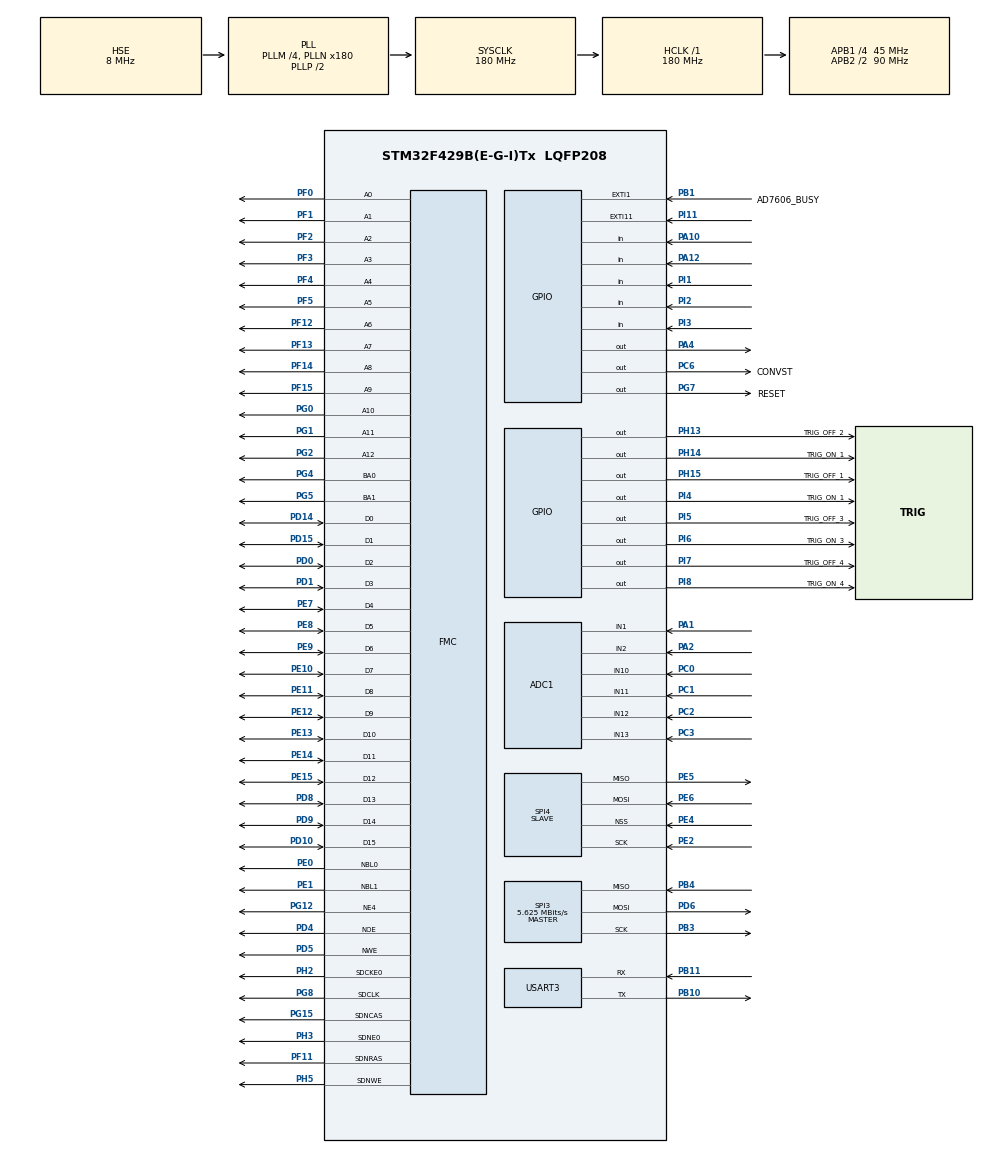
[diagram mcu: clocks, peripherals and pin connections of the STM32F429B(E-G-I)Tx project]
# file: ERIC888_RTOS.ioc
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ADC1.Channel-0\#ChannelRegularConversion=ADC_CHANNEL_1
ADC1.Channel-1\#ChannelRegularConversion=ADC_CHANNEL_2
ADC1.Channel-2\#ChannelRegularConversion=ADC_CHANNEL_10
ADC1.Channel-3\#ChannelRegularConversion=ADC_CHANNEL_11
ADC1.Channel-4\#ChannelRegularConversion=ADC_CHANNEL_12
ADC1.Channel-5\#ChannelRegularConversion=ADC_CHANNEL_13
ADC1.DMAContinuousRequests=ENABLE
ADC1.ExternalTrigConv=ADC_EXTERNALTRIGCONV_T3_TRGO
ADC1.NbrOfConversion=6
ADC1.NbrOfConversionFlag=1
ADC1.Rank-0\#ChannelRegularConversion=1
ADC1.Rank-1\#ChannelRegularConversion=2
ADC1.Rank-2\#ChannelRegularConversion=3
ADC1.Rank-3\#ChannelRegularConversion=4
ADC1.Rank-4\#ChannelRegularConversion=5
ADC1.Rank-5\#ChannelRegularConversion=6
ADC1.SamplingTime-0\#ChannelRegularConversion=ADC_SAMPLETIME_84CYCLES
ADC1.SamplingTime-1\#ChannelRegularConversion=ADC_SAMPLETIME_84CYCLES
ADC1.SamplingTime-2\#ChannelRegularConversion=ADC_SAMPLETIME_84CYCLES
ADC1.SamplingTime-3\#ChannelRegularConversion=ADC_SAMPLETIME_84CYCLES
ADC1.SamplingTime-4\#ChannelRegularConversion=ADC_SAMPLETIME_84CYCLES
ADC1.SamplingTime-5\#ChannelRegularConversion=ADC_SAMPLETIME_84CYCLES
ADC1.ScanConvMode=ENABLE
ADC1.master=1
Dma.ADC1.2.Direction=DMA_PERIPH_TO_MEMORY
Dma.ADC1.2.FIFOMode=DMA_FIFOMODE_DISABLE
Dma.ADC1.2.Instance=DMA2_Stream4
Dma.ADC1.2.MemDataAlignment=DMA_MDATAALIGN_HALFWORD
Dma.ADC1.2.MemInc=DMA_MINC_ENABLE
Dma.ADC1.2.Mode=DMA_CIRCULAR
Dma.ADC1.2.PeriphDataAlignment=DMA_PDATAALIGN_HALFWORD
Dma.ADC1.2.PeriphInc=DMA_PINC_DISABLE
Dma.ADC1.2.Priority=DMA_PRIORITY_LOW
Dma.Request0=SPI4_RX
Dma.Request1=SPI4_TX
Dma.Request2=ADC1
Dma.SPI4_RX.0.Direction=DMA_PERIPH_TO_MEMORY
Dma.SPI4_RX.0.FIFOMode=DMA_FIFOMODE_DISABLE
Dma.SPI4_RX.0.Instance=DMA2_Stream0
Dma.SPI4_RX.0.MemDataAlignment=DMA_MDATAALIGN_HALFWORD
Dma.SPI4_RX.0.MemInc=DMA_MINC_ENABLE
Dma.SPI4_RX.0.Mode=DMA_CIRCULAR
Dma.SPI4_RX.0.PeriphDataAlignment=DMA_PDATAALIGN_HALFWORD
Dma.SPI4_RX.0.PeriphInc=DMA_PINC_DISABLE
Dma.SPI4_RX.0.Priority=DMA_PRIORITY_VERY_HIGH
Dma.SPI4_TX.1.Direction=DMA_MEMORY_TO_PERIPH
Dma.SPI4_TX.1.FIFOMode=DMA_FIFOMODE_DISABLE
Dma.SPI4_TX.1.Instance=DMA2_Stream1
Dma.SPI4_TX.1.MemDataAlignment=DMA_MDATAALIGN_HALFWORD
Dma.SPI4_TX.1.MemInc=DMA_MINC_ENABLE
Dma.SPI4_TX.1.Mode=DMA_CIRCULAR
Dma.SPI4_TX.1.PeriphDataAlignment=DMA_PDATAALIGN_HALFWORD
Dma.SPI4_TX.1.PeriphInc=DMA_PINC_DISABLE
Dma.SPI4_TX.1.Priority=DMA_PRIORITY_VERY_HIGH
FMC.AddressSetupTime4=2
FMC.BusTurnAroundDuration4=2
FMC.CASLatency1=FMC_SDRAM_CAS_LATENCY_3
FMC.ColumnBitsNumber1=FMC_SDRAM_COLUMN_BITS_NUM_9
FMC.DataSetupTime4=6
FMC.ExitSelfRefreshDelay1=7
FMC.LoadToActiveDelay1=2
FMC.RCDDelay1=2
FMC.RPDelay1=2
FMC.RowCycleDelay1=7
FMC.SDClockPeriod1=FMC_SDRAM_CLOCK_PERIOD_2
FMC.SelfRefreshTime1=4
FMC.WriteOperation4=FMC_WRITE_OPERATION_ENABLE
FMC.WriteRecoveryTime1=3
FREERTOS.Tasks01=Task_01,0,512,StartTask01,Default,NULL,Dynamic,NULL,NULL;myTask_Calc,1,1024,StartTaskCalc,Default,NULL,Dynamic,NULL,NULL;myTask_Store,1,512,StartTaskStore,Default,NULL,Dynamic,NULL,NULL;myTask_Monitor,-2,256,StartTaskMonitor,Default,NULL,Dynamic,NULL,NULL
FREERTOS.configTOTAL_HEAP_SIZE=32768
IWDG.Prescaler=IWDG_PRESCALER_64
IWDG.Reload=1000
Mcu.Family=STM32F4
Mcu.Name=STM32F429B(E-G-I)Tx
Mcu.Package=LQFP208
NVIC.DMA2_Stream0_IRQn=true\:5\:0\:false\:false\:true\:true\:false\:true\:true
NVIC.DMA2_Stream1_IRQn=true\:5\:0\:false\:false\:true\:true\:false\:true\:true
NVIC.DMA2_Stream4_IRQn=true\:5\:0\:false\:false\:true\:true\:false\:true\:true
NVIC.EXTI1_IRQn=true\:5\:0\:false\:false\:true\:true\:true\:true\:true
NVIC.PriorityGroup=NVIC_PRIORITYGROUP_4
NVIC.TIM2_IRQn=true\:6\:0\:true\:false\:true\:true\:true\:true\:true
NVIC.TIM6_DAC_IRQn=true\:0\:0\:true\:false\:true\:false\:false\:true\:true
NVIC.TimeBase=TIM6_DAC_IRQn
NVIC.TimeBaseIP=TIM6
PA1.Signal=ADCx_IN1
PA10.Signal=GPIO_Input
PA12.Signal=GPIO_Input
PA13.Mode=Serial_Wire
PA13.Signal=SYS_JTMS-SWDIO
PA14.Mode=Serial_Wire
PA14.Signal=SYS_JTCK-SWCLK
PA2.Signal=ADCx_IN2
PA4.PinState=GPIO_PIN_SET
PA4.Signal=GPIO_Output
PB1.GPIO_Label=AD7606_BUSY
PB1.GPIO_ModeDefaultEXTI=GPIO_MODE_IT_FALLING
PB1.GPIO_PuPd=GPIO_PULLUP
PB1.Signal=GPXTI1
PB10.Mode=Asynchronous
PB10.Signal=USART3_TX
PB11.Mode=Asynchronous
PB11.Signal=USART3_RX
PB3.Mode=Full_Duplex_Master
PB3.Signal=SPI3_SCK
PB4.Mode=Full_Duplex_Master
PB4.Signal=SPI3_MISO
PB6.Signal=I2C1_SCL
PB9.Signal=I2C1_SDA
PC0.Signal=ADCx_IN10
PC1.Signal=ADCx_IN11
PC2.Signal=ADCx_IN12
PC3.Signal=ADCx_IN13
PC6.GPIO_Label=CONVST
PC6.Signal=GPIO_Output
PD0.Signal=FMC_D2_DA2
PD1.Signal=FMC_D3_DA3
PD10.Signal=FMC_D15_DA15
PD14.Signal=FMC_D0_DA0
PD15.Signal=FMC_D1_DA1
PD4.Signal=FMC_NOE
PD5.Signal=FMC_NWE
PD6.Mode=Full_Duplex_Master
PD6.Signal=SPI3_MOSI
PD8.Signal=FMC_D13_DA13
PD9.Signal=FMC_D14_DA14
PE0.Signal=FMC_NBL0
PE1.Signal=FMC_NBL1
PE10.Signal=FMC_D7_DA7
PE11.Signal=FMC_D8_DA8
PE12.Signal=FMC_D9_DA9
PE13.Signal=FMC_D10_DA10
PE14.Signal=FMC_D11_DA11
PE15.Signal=FMC_D12_DA12
PE2.Mode=Full_Duplex_Slave
PE2.Signal=SPI4_SCK
PE4.Mode=NSS_Signal_Hard_Input
PE4.Signal=SPI4_NSS
PE5.Mode=Full_Duplex_Slave
PE5.Signal=SPI4_MISO
PE6.Mode=Full_Duplex_Slave
PE6.Signal=SPI4_MOSI
PE7.Signal=FMC_D4_DA4
PE8.Signal=FMC_D5_DA5
PE9.Signal=FMC_D6_DA6
PF0.Signal=FMC_A0
PF1.Signal=FMC_A1
PF11.Signal=FMC_SDNRAS
PF12.Signal=FMC_A6
PF13.Signal=FMC_A7
PF14.Signal=FMC_A8
PF15.Signal=FMC_A9
PF2.Signal=FMC_A2
PF3.Signal=FMC_A3
PF4.Signal=FMC_A4
PF5.Signal=FMC_A5
PG0.Signal=FMC_A10
PG1.Signal=FMC_A11
PG12.Mode=NorPsramChipSelect4_4
PG12.Signal=FMC_NE4
PG15.Signal=FMC_SDNCAS
PG2.Signal=FMC_A12
PG4.Signal=FMC_A14_BA0
PG5.Signal=FMC_A15_BA1
PG7.GPIO_Label=RESET
PG7.Signal=GPIO_Output
PG8.Signal=FMC_SDCLK
PH0/OSC_IN.Mode=HSE-External-Oscillator
PH0/OSC_IN.Signal=RCC_OSC_IN
PH1/OSC_OUT.Mode=HSE-External-Oscillator
PH1/OSC_OUT.Signal=RCC_OSC_OUT
PH13.GPIO_Label=TRIG_OFF_2
PH13.GPIO_ModeDefaultOutputPP=GPIO_MODE_OUTPUT_PP
PH13.GPIO_PuPd=GPIO_NOPULL
PH13.GPIO_Speed=GPIO_SPEED_FREQ_VERY_HIGH
PH13.Signal=GPIO_Output
PH14.GPIO_Label=TRIG_ON_1
PH14.GPIO_ModeDefaultOutputPP=GPIO_MODE_OUTPUT_PP
PH14.GPIO_PuPd=GPIO_NOPULL
PH14.GPIO_Speed=GPIO_SPEED_FREQ_VERY_HIGH
PH14.Signal=GPIO_Output
PH15.GPIO_Label=TRIG_OFF_1
PH15.GPIO_ModeDefaultOutputPP=GPIO_MODE_OUTPUT_PP
PH15.GPIO_PuPd=GPIO_NOPULL
PH15.GPIO_Speed=GPIO_SPEED_FREQ_VERY_HIGH
PH15.Signal=GPIO_Output
PH2.Mode=SdramChipSelect1_1
PH2.Signal=FMC_SDCKE0
PH3.Mode=SdramChipSelect1_1
PH3.Signal=FMC_SDNE0
PH5.Signal=FMC_SDNWE
PI1.Signal=GPIO_Input
PI11.Signal=GPXTI11
PI2.Signal=GPIO_Input
PI3.Signal=GPIO_Input
PI4.GPIO_Label=TRIG_ON_1
PI4.GPIO_ModeDefaultOutputPP=GPIO_MODE_OUTPUT_PP
PI4.GPIO_PuPd=GPIO_NOPULL
PI4.GPIO_Speed=GPIO_SPEED_FREQ_VERY_HIGH
PI4.PinState=GPIO_PIN_RESET
PI4.Signal=GPIO_Output
PI5.GPIO_Label=TRIG_OFF_3
PI5.GPIO_ModeDefaultOutputPP=GPIO_MODE_OUTPUT_PP
PI5.GPIO_PuPd=GPIO_NOPULL
PI5.GPIO_Speed=GPIO_SPEED_FREQ_VERY_HIGH
PI5.Signal=GPIO_Output
PI6.GPIO_Label=TRIG_ON_3
PI6.GPIO_ModeDefaultOutputPP=GPIO_MODE_OUTPUT_PP
PI6.GPIO_PuPd=GPIO_NOPULL
PI6.GPIO_Speed=GPIO_SPEED_FREQ_VERY_HIGH
PI6.Signal=GPIO_Output
PI7.GPIO_Label=TRIG_OFF_4
PI7.GPIO_ModeDefaultOutputPP=GPIO_MODE_OUTPUT_PP
PI7.GPIO_PuPd=GPIO_NOPULL
PI7.GPIO_Speed=GPIO_SPEED_FREQ_VERY_HIGH
PI7.Signal=GPIO_Output
PI8.GPIO_Label=TRIG_ON_4
PI8.GPIO_ModeDefaultOutputPP=GPIO_MODE_OUTPUT_PP
PI8.GPIO_PuPd=GPIO_NOPULL
PI8.GPIO_Speed=GPIO_SPEED_FREQ_LOW
PI8.PinState=GPIO_PIN_RESET
PI8.Signal=GPIO_Output
ProjectManager.HeapSize=0x200
ProjectManager.StackSize=0x400
ProjectManager.TargetToolchain=Makefile
RCC.48MHZClocksFreq_Value=90000000
RCC.AHBFreq_Value=180000000
RCC.APB1CLKDivider=RCC_HCLK_DIV4
RCC.APB1Freq_Value=45000000
RCC.APB1TimFreq_Value=90000000
RCC.APB2CLKDivider=RCC_HCLK_DIV2
RCC.APB2Freq_Value=90000000
RCC.APB2TimFreq_Value=180000000
RCC.CortexFreq_Value=180000000
RCC.HCLKFreq_Value=180000000
RCC.HSE_VALUE=8000000
RCC.HSI_VALUE=16000000
RCC.LSE_VALUE=32768
RCC.PLLM=4
RCC.PLLN=180
RCC.PLLSourceVirtual=RCC_PLLSOURCE_HSE
RCC.SYSCLKFreq_VALUE=180000000
RCC.SYSCLKSource=RCC_SYSCLKSOURCE_PLLCLK
RCC.VCOOutputFreq_Value=360000000
SH.ADCx_IN1.0=ADC1_IN1,IN1
SH.ADCx_IN10.0=ADC1_IN10,IN10
SH.ADCx_IN11.0=ADC1_IN11,IN11
SH.ADCx_IN12.0=ADC1_IN12,IN12
SH.ADCx_IN13.0=ADC1_IN13,IN13
SH.ADCx_IN2.0=ADC1_IN2,IN2
SH.FMC_A0.0=FMC_A0,13b-sda1
SH.FMC_A0.1=FMC_A0,1b-a4
SH.FMC_A1.0=FMC_A1,13b-sda1
SH.FMC_A10.0=FMC_A10,13b-sda1
SH.FMC_A11.0=FMC_A11,13b-sda1
SH.FMC_A12.0=FMC_A12,13b-sda1
SH.FMC_A14_BA0.0=FMC_BA0,FourSdramBanks1
SH.FMC_A15_BA1.0=FMC_BA1,FourSdramBanks1
SH.FMC_A2.0=FMC_A2,13b-sda1
SH.FMC_A3.0=FMC_A3,13b-sda1
SH.FMC_A4.0=FMC_A4,13b-sda1
SH.FMC_A5.0=FMC_A5,13b-sda1
SH.FMC_A6.0=FMC_A6,13b-sda1
SH.FMC_A7.0=FMC_A7,13b-sda1
SH.FMC_A8.0=FMC_A8,13b-sda1
SH.FMC_A9.0=FMC_A9,13b-sda1
SH.FMC_D0_DA0.0=FMC_D0,sd-16b-d1
SH.FMC_D0_DA0.1=FMC_D0,16b-d4
SH.FMC_D10_DA10.0=FMC_D10,sd-16b-d1
SH.FMC_D10_DA10.1=FMC_D10,16b-d4
SH.FMC_D11_DA11.0=FMC_D11,sd-16b-d1
SH.FMC_D11_DA11.1=FMC_D11,16b-d4
SH.FMC_D12_DA12.0=FMC_D12,sd-16b-d1
SH.FMC_D12_DA12.1=FMC_D12,16b-d4
SH.FMC_D13_DA13.0=FMC_D13,sd-16b-d1
SH.FMC_D13_DA13.1=FMC_D13,16b-d4
SH.FMC_D14_DA14.0=FMC_D14,sd-16b-d1
SH.FMC_D14_DA14.1=FMC_D14,16b-d4
SH.FMC_D15_DA15.0=FMC_D15,sd-16b-d1
SH.FMC_D15_DA15.1=FMC_D15,16b-d4
SH.FMC_D1_DA1.0=FMC_D1,sd-16b-d1
SH.FMC_D1_DA1.1=FMC_D1,16b-d4
SH.FMC_D2_DA2.0=FMC_D2,sd-16b-d1
SH.FMC_D2_DA2.1=FMC_D2,16b-d4
SH.FMC_D3_DA3.0=FMC_D3,sd-16b-d1
SH.FMC_D3_DA3.1=FMC_D3,16b-d4
SH.FMC_D4_DA4.0=FMC_D4,sd-16b-d1
SH.FMC_D4_DA4.1=FMC_D4,16b-d4
SH.FMC_D5_DA5.0=FMC_D5,sd-16b-d1
SH.FMC_D5_DA5.1=FMC_D5,16b-d4
SH.FMC_D6_DA6.0=FMC_D6,sd-16b-d1
SH.FMC_D6_DA6.1=FMC_D6,16b-d4
SH.FMC_D7_DA7.0=FMC_D7,sd-16b-d1
SH.FMC_D7_DA7.1=FMC_D7,16b-d4
SH.FMC_D8_DA8.0=FMC_D8,sd-16b-d1
SH.FMC_D8_DA8.1=FMC_D8,16b-d4
SH.FMC_D9_DA9.0=FMC_D9,sd-16b-d1
SH.FMC_D9_DA9.1=FMC_D9,16b-d4
SH.FMC_NBL0.0=FMC_NBL0,Sd2ByteEnable1
SH.FMC_NBL1.0=FMC_NBL1,Sd2ByteEnable1
SH.FMC_NOE.0=FMC_NOE,Sram4
SH.FMC_NWE.0=FMC_NWE,Sram4
SH.FMC_SDCLK.0=FMC_SDCLK,13b-sda1
SH.FMC_SDNCAS.0=FMC_SDNCAS,13b-sda1
SH.FMC_SDNRAS.0=FMC_SDNRAS,13b-sda1
SH.FMC_SDNWE.0=FMC_SDNWE,13b-sda1
SPI3.BaudRatePrescaler=SPI_BAUDRATEPRESCALER_8
SPI3.CalculateBaudRate=5.625 MBits/s
SPI3.Direction=SPI_DIRECTION_2LINES
SPI3.Mode=SPI_MODE_MASTER
SPI3.VirtualType=VM_MASTER
SPI4.DataSize=SPI_DATASIZE_16BIT
SPI4.Direction=SPI_DIRECTION_2LINES
SPI4.Mode=SPI_MODE_SLAVE
SPI4.VirtualNSS=VM_NSSHARD
SPI4.VirtualType=VM_SLAVE
TIM2.AutoReloadPreload=TIM_AUTORELOAD_PRELOAD_ENABLE
TIM2.Period=99
TIM2.Prescaler=89
TIM3.Period=3515
TIM3.Prescaler=0
TIM3.TIM_MasterOutputTrigger=TIM_TRGO_UPDATE
USART3.VirtualMode=VM_ASYNC
VP_FREERTOS_VS_CMSIS_V1.Mode=CMSIS_V1
VP_IWDG_VS_IWDG.Mode=IWDG_Activate
VP_SYS_VS_tim6.Mode=TIM6
VP_TIM2_VS_ClockSourceINT.Mode=Internal
VP_TIM3_VS_ClockSourceINT.Mode=Internal
board=custom

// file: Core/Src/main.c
/* USER CODE BEGIN Header */
/**
 ******************************************************************************
 * @file           : main.c
 * @brief          : Main program body
 ******************************************************************************
 * @attention
 *
 * Copyright (c) 2026 STMicroelectronics.
 * All rights reserved.
 *
 * This software is licensed under terms that can be found in the LICENSE file
 * in the root directory of this software component.
 * If no LICENSE file comes with this software, it is provided AS-IS.
 *
 ******************************************************************************
 */
/* USER CODE END Header */
#include "main.h"
#include "cmsis_os.h"
#include "adc.h"
#include "dma.h"
#include "iwdg.h"
#include "spi.h"
#include "tim.h"
#include "usart.h"
#include "gpio.h"
#include "fmc.h"

/* USER CODE BEGIN Includes */
#include "bsp_sdram.h"
#include "bsp_ad7606.h"
#include "bsp_adc.h"
#include "bsp_kswitch.h"
#include "bsp_rs485.h"
#include "bsp_spiflash.h"
/* USER CODE END Includes */

/* USER CODE BEGIN PD */
// ERIC888 快切点火核心：AD7606 挂载在 FMC NE4，基地址 0x6C000000
#define AD7606_BASE_ADDR ((uint32_t)0x6C000000)
/* USER CODE END PD */

/* USER CODE BEGIN PV */
// 定义一个全局数组，用来存储 8 个通道的电压/电流实时数据
int16_t ad7606_data[8];
uint16_t adc_dma_buf[6];  // ADC1 DMA circular buffer (6 channels)
/* USER CODE END PV */

void SystemClock_Config(void);
void MX_FREERTOS_Init(void);

int main(void)
{

  /* MCU Configuration--------------------------------------------------------*/

  /* Reset of all peripherals, Initializes the Flash interface and the Systick. */
  HAL_Init();

  /* Configure the system clock */
  SystemClock_Config();

  /* Initialize all configured peripherals */
  MX_GPIO_Init();
  MX_DMA_Init();
  MX_FMC_Init();
  MX_SPI4_Init();
  MX_USART3_UART_Init();
  MX_ADC1_Init();
  MX_IWDG_Init();
  MX_TIM3_Init();
  MX_SPI3_Init();
  MX_TIM2_Init();
  /* USER CODE BEGIN 2 */
  // --- IO 补偿单元：180MHz 下 Very High 速率引脚必须开启 ---
  __HAL_RCC_SYSCFG_CLK_ENABLE();
  SYSCFG->CMPCR |= SYSCFG_CMPCR_CMP_PD;
  while (!(SYSCFG->CMPCR & SYSCFG_CMPCR_READY)) {}

  // --- PI8 (TRIG_ON_4) 速率强推 Very High (CubeMX 限制为 Low) ---
  GPIOI->OSPEEDR |= (3U << (8 * 2));  // bit[17:16] = 0b11

  // --- SDRAM 初始化序列 (W9825G6KH) ---
  if (BSP_SDRAM_Init(&hsdram1) != 0) {
    Error_Handler();  // SDRAM 初始化失败
  }

  // --- SDRAM 读写测试 (4KB) ---
  volatile int sdram_test_result = BSP_SDRAM_Test();
  // sdram_test_result: 0=通过, -1=失败，可通过调试器查看

  // --- AD7606 hardware reset ---
  BSP_AD7606_Reset();

  // --- SPI Flash init (SPI3 manual) ---
  BSP_SpiFlash_Init();
  volatile uint32_t flash_id = BSP_SpiFlash_ReadID();
  // flash_id: e.g. 0xEF4018 (W25Q128), check via debugger

  // --- ADC1 DMA start (TIM3 25.6kHz trigger, 6 channels) ---
  BSP_ADC_Start(&hadc1, &htim3, adc_dma_buf);

  // --- TIM3 CH1: hardware PWM CONVST at 25.6kHz (zero-ISR, zero-jitter) ---
  // TIM3 TRGO=Update triggers ADC; CH1 PWM outputs CONVST pulse on PC6
  HAL_TIM_PWM_Start(&htim3, TIM_CHANNEL_1);

  // --- EXTI1 (PB1 BUSY): priority=4, preempts SPI/UART(5+) ---
  // configLIBRARY_MAX_SYSCALL_INTERRUPT_PRIORITY=4, so FromISR APIs are safe
  HAL_NVIC_SetPriority(EXTI1_IRQn, 4, 0);
  /* USER CODE END 2 */

  /* Call init function for freertos objects (in cmsis_os2.c) */
  MX_FREERTOS_Init();

  /* Start scheduler */
  osKernelStart();

  /* We should never get here as control is now taken by the scheduler */

  /* Infinite loop */
  while (1) {

    /* USER CODE BEGIN 3 */
    // FreeRTOS scheduler took over, this loop is never reached
  }
  /* USER CODE END 3 */
}

void SystemClock_Config(void)
{
  RCC_OscInitTypeDef RCC_OscInitStruct = {0};
  RCC_ClkInitTypeDef RCC_ClkInitStruct = {0};

  /** Configure the main internal regulator output voltage
  */
  __HAL_RCC_PWR_CLK_ENABLE();
  __HAL_PWR_VOLTAGESCALING_CONFIG(PWR_REGULATOR_VOLTAGE_SCALE1);

  /** Initializes the RCC Oscillators according to the specified parameters
  * in the RCC_OscInitTypeDef structure.
  */
  RCC_OscInitStruct.OscillatorType = RCC_OSCILLATORTYPE_LSI|RCC_OSCILLATORTYPE_HSE;
  RCC_OscInitStruct.HSEState = RCC_HSE_ON;
  RCC_OscInitStruct.LSIState = RCC_LSI_ON;
  RCC_OscInitStruct.PLL.PLLState = RCC_PLL_ON;
  RCC_OscInitStruct.PLL.PLLSource = RCC_PLLSOURCE_HSE;
  RCC_OscInitStruct.PLL.PLLM = 4;
  RCC_OscInitStruct.PLL.PLLN = 180;
  RCC_OscInitStruct.PLL.PLLP = RCC_PLLP_DIV2;
  RCC_OscInitStruct.PLL.PLLQ = 4;
  if (HAL_RCC_OscConfig(&RCC_OscInitStruct) != HAL_OK)
  {
    Error_Handler();
  }

  /** Activate the Over-Drive mode
  */
  if (HAL_PWREx_EnableOverDrive() != HAL_OK)
  {
    Error_Handler();
  }

  /** Initializes the CPU, AHB and APB buses clocks
  */
  RCC_ClkInitStruct.ClockType = RCC_CLOCKTYPE_HCLK|RCC_CLOCKTYPE_SYSCLK
                              |RCC_CLOCKTYPE_PCLK1|RCC_CLOCKTYPE_PCLK2;
  RCC_ClkInitStruct.SYSCLKSource = RCC_SYSCLKSOURCE_PLLCLK;
  RCC_ClkInitStruct.AHBCLKDivider = RCC_SYSCLK_DIV1;
  RCC_ClkInitStruct.APB1CLKDivider = RCC_HCLK_DIV4;
  RCC_ClkInitStruct.APB2CLKDivider = RCC_HCLK_DIV2;

  if (HAL_RCC_ClockConfig(&RCC_ClkInitStruct, FLASH_LATENCY_5) != HAL_OK)
  {
    Error_Handler();
  }
}

void HAL_TIM_PeriodElapsedCallback(TIM_HandleTypeDef *htim)
{
  if (htim->Instance == TIM6)
  {
    HAL_IncTick();
  }
}

void Error_Handler(void)
{
  __disable_irq();
  while (1) {
  }
}
#ifdef USE_FULL_ASSERT
/**
  * @brief  Reports the name of the source file and the source line number
  *         where the assert_param error has occurred.
  * @param  file: pointer to the source file name
  * @param  line: assert_param error line source number
  * @retval None
  */
void assert_failed(uint8_t *file, uint32_t line)
{
  /* USER CODE BEGIN 6 */
  /* User can add his own implementation to report the file name and line
     number, ex: printf("Wrong parameters value: file %s on line %d\r\n", file,
     line) */
  /* USER CODE END 6 */
}
#endif /* USE_FULL_ASSERT */

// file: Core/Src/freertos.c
/* USER CODE BEGIN Header */
/**
  ******************************************************************************
  * File Name          : freertos.c
  * Description        : Code for freertos applications
  ******************************************************************************
  * @attention
  *
  * Copyright (c) 2026 STMicroelectronics.
  * All rights reserved.
  *
  * This software is licensed under terms that can be found in the LICENSE file
  * in the root directory of this software component.
  * If no LICENSE file comes with this software, it is provided AS-IS.
  *
  ******************************************************************************
  */
/* USER CODE END Header */

#include "FreeRTOS.h"
#include "task.h"
#include "main.h"
#include "cmsis_os.h"

/* USER CODE BEGIN Includes */
#include "bsp_ad7606.h"
#include "bsp_adc.h"
#include "bsp_kswitch.h"
#include "bsp_rs485.h"
#include "bsp_sdram.h"
#include "adc.h"
#include "tim.h"
#include "usart.h"
#include "iwdg.h"
#include "eric888_spi_protocol.h"
#include "bsp_spi_slave.h"
#include "spi.h"
#include "dsp_calc.h"
#include "fault_recorder.h"
#include "modbus_rtu.h"
/* USER CODE END Includes */

/* USER CODE BEGIN Variables */
extern uint16_t adc_dma_buf[6];
extern volatile uint32_t g_isr_count;
extern volatile uint32_t g_isr_cycles_max;

/* Task notification handle - used by EXTI1 ISR to wake Calc task */
volatile TaskHandle_t xCalcTaskHandle = NULL;

/* Ping-pong double buffer: ISR writes, Task reads, zero-race */
Eric888_DoubleBuffer g_adc_db;

/* Batch ring buffer: 2 x 512 samples in SDRAM for SPI bulk transfer */
Eric888_BatchRing g_batch_ring __attribute__((section(".sdram")));
/* NOTE: if .sdram section is not defined in linker, place in BSS: */
/* Eric888_BatchRing g_batch_ring; */
/* USER CODE END Variables */
osThreadId Task_01Handle;
osThreadId myTask_CalcHandle;
osThreadId myTask_StoreHandle;
osThreadId myTask_MonitorHandle;

void StartTask01(void const * argument);
void StartTaskCalc(void const * argument);
void StartTaskStore(void const * argument);
void StartTaskMonitor(void const * argument);

void MX_FREERTOS_Init(void); /* (MISRA C 2004 rule 8.1) */

/* GetIdleTaskMemory prototype (linked to static allocation support) */
void vApplicationGetIdleTaskMemory( StaticTask_t **ppxIdleTaskTCBBuffer, StackType_t **ppxIdleTaskStackBuffer, uint32_t *pulIdleTaskStackSize );

/* USER CODE BEGIN GET_IDLE_TASK_MEMORY */
static StaticTask_t xIdleTaskTCBBuffer;
static StackType_t xIdleStack[configMINIMAL_STACK_SIZE];

void vApplicationGetIdleTaskMemory( StaticTask_t **ppxIdleTaskTCBBuffer, StackType_t **ppxIdleTaskStackBuffer, uint32_t *pulIdleTaskStackSize )
{
  *ppxIdleTaskTCBBuffer = &xIdleTaskTCBBuffer;
  *ppxIdleTaskStackBuffer = &xIdleStack[0];
  *pulIdleTaskStackSize = configMINIMAL_STACK_SIZE;
  /* place for user code */
}
/* USER CODE END GET_IDLE_TASK_MEMORY */

/* GetTimerTaskMemory prototype (required when configUSE_TIMERS=1 + static alloc) */
void vApplicationGetTimerTaskMemory( StaticTask_t **ppxTimerTaskTCBBuffer, StackType_t **ppxTimerTaskStackBuffer, uint32_t *pulTimerTaskStackSize );

static StaticTask_t xTimerTaskTCBBuffer;
static StackType_t xTimerStack[configTIMER_TASK_STACK_DEPTH];

void vApplicationGetTimerTaskMemory( StaticTask_t **ppxTimerTaskTCBBuffer, StackType_t **ppxTimerTaskStackBuffer, uint32_t *pulTimerTaskStackSize )
{
  *ppxTimerTaskTCBBuffer = &xTimerTaskTCBBuffer;
  *ppxTimerTaskStackBuffer = &xTimerStack[0];
  *pulTimerTaskStackSize = configTIMER_TASK_STACK_DEPTH;
}

void MX_FREERTOS_Init(void) {

  /* Create the thread(s) */
  /* definition and creation of Task_01 */
  osThreadDef(Task_01, StartTask01, osPriorityNormal, 0, 512);
  Task_01Handle = osThreadCreate(osThread(Task_01), NULL);

  /* definition and creation of myTask_Calc */
  osThreadDef(myTask_Calc, StartTaskCalc, osPriorityAboveNormal, 0, 1024);
  myTask_CalcHandle = osThreadCreate(osThread(myTask_Calc), NULL);

  /* definition and creation of myTask_Store */
  osThreadDef(myTask_Store, StartTaskStore, osPriorityAboveNormal, 0, 512);
  myTask_StoreHandle = osThreadCreate(osThread(myTask_Store), NULL);

  /* definition and creation of myTask_Monitor */
  osThreadDef(myTask_Monitor, StartTaskMonitor, osPriorityLow, 0, 256);
  myTask_MonitorHandle = osThreadCreate(osThread(myTask_Monitor), NULL);

}

void StartTask01(void const * argument)
{
  /* USER CODE BEGIN StartTask01 */
  /* Communication task: SPI4 inter-board + RS485 Modbus */
  BSP_RS485_Init();
  BSP_SpiSlave_Init(&hspi4);
  Modbus_Init(&huart3);

  for(;;)
  {
    /* Refresh SPI TX mirror with latest ADC data from double-buffer */
    if (Eric888_DB_HasFresh(&g_adc_db)) {
      BSP_SpiSlave_RefreshTx(&g_adc_db);
    }

    /* Handle RS485 Modbus RTU requests (blocking with timeout) */
    Modbus_Poll();
  }
  /* USER CODE END StartTask01 */
}

void StartTaskCalc(void const * argument)
{
  /* USER CODE BEGIN StartTaskCalc */
  /* Save handle for ISR notification */
  xCalcTaskHandle = xTaskGetCurrentTaskHandle();

  /* Initialize K-switch driver (requires RTOS scheduler running) */
  BSP_KSwitch_Init();

  /* Initialize double-buffer */
  Eric888_DB_Init(&g_adc_db);
  Eric888_Batch_Init(&g_batch_ring);
  DSP_Init();

  for(;;)
  {
    /* Block until EXTI1 ISR notifies us (AD7606 data ready in ad7606_data[]) */
    ulTaskNotifyTake(pdTRUE, portMAX_DELAY);

    /* Check if batch ring read-side has a complete 512-sample block */
    if (g_batch_ring.read_ready) {
      const Eric888_BatchBank *batch = Eric888_Batch_GetReadBank(&g_batch_ring);
      const DSP_Results *dsp = DSP_ProcessBatch(batch->samples);
      /* Protection trip if needed */
      if (dsp->trip_requested) {
        BSP_KSwitch_TripAll();

        /* Post fault event to StoreTask for Flash recording */
        FaultEvent evt;
        evt.timestamp_ms  = HAL_GetTick();
        evt.fault_flags   = dsp->fault_flags;
        evt.fault_channel = 0;
        /* Find primary faulted channel (first set bit) */
        for (int fc = 0; fc < DSP_NUM_CH; fc++) {
          if (dsp->fault_flags & (1 << fc)) {
            evt.fault_channel = (uint8_t)fc;
            break;
          }
        }
        evt.dsp_snapshot = *dsp;
        /* Send faulted channel waveform (int16_t raw from batch) */
        int16_t wave_buf[512];
        for (int wi = 0; wi < 512; wi++) {
          wave_buf[wi] = batch->samples[wi].ch[evt.fault_channel];
        }
        FaultRecorder_PostEvent(&evt, wave_buf, 512);
      }
    }
  }
  /* USER CODE END StartTaskCalc */
}

void StartTaskStore(void const * argument)
{
  /* USER CODE BEGIN StartTaskStore */
  /* Initialize fault recorder (creates queue, reads Flash metadata) */
  FaultRecorder_Init();

  for(;;)
  {
    /* Block on fault event queue — writes to SPI Flash when event arrives */
    FaultRecorder_ProcessTask();
  }
  /* USER CODE END StartTaskStore */
}

void StartTaskMonitor(void const * argument)
{
  /* USER CODE BEGIN StartTaskMonitor */
  static uint32_t led_toggle_cnt = 0;
  static uint32_t last_isr_count = 0;
  static uint32_t stats_tick = 0;

  for(;;)
  {
    /* Feed IWDG watchdog */
    HAL_IWDG_Refresh(&hiwdg);

    /* Heartbeat LED: toggle every 500ms (5 × 100ms loop) */
    if (++led_toggle_cnt >= 5) {
      led_toggle_cnt = 0;
      HAL_GPIO_TogglePin(GPIOA, GPIO_PIN_0); /* PA0 = heartbeat LED (adjust if needed) */
    }

    /* ISR statistics: check sampling frequency every 5s */
    uint32_t now = HAL_GetTick();
    if ((now - stats_tick) >= 5000) {
      uint32_t cur_count = g_isr_count;
      uint32_t delta = cur_count - last_isr_count;
      /* Expected: ~128000 interrupts per 5s (25600 Hz × 5s) */
      /* Alert if deviation > 5% */
      if (delta < 121600 || delta > 134400) {
        /* Sampling frequency anomaly detected!
         * In production: set a fault flag or send alert via SPI/RS485 */
      }
      last_isr_count = cur_count;
      stats_tick = now;
    }

    osDelay(100);  /* 100ms watchdog feed interval */
  }
  /* USER CODE END StartTaskMonitor */
}

/* USER CODE BEGIN Application */
/**
 * @brief SPI TX/RX DMA complete callback
 *        Called when B-board completes a full-duplex SPI transaction
 */
void HAL_SPI_TxRxCpltCallback(SPI_HandleTypeDef *hspi)
{
  if (hspi->Instance == SPI4) {
    BSP_SpiSlave_DmaComplete(hspi);
  }
}
/* USER CODE END Application */
